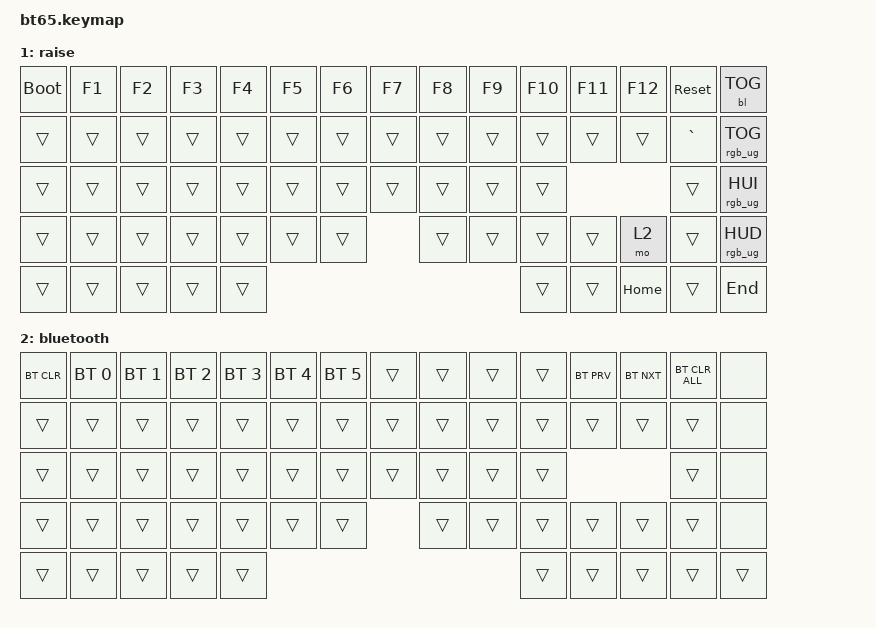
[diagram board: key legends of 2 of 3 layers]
#include <behaviors.dtsi>
#include <dt-bindings/zmk/keys.h>
#include <dt-bindings/zmk/bt.h>
#include <dt-bindings/zmk/rgb.h>
#include <dt-bindings/zmk/backlight.h>
#include <dt-bindings/zmk/ext_power.h>


/ {
    behaviors {
        bl_encoder: bl_encoder {
            compatible = "zmk,behavior-sensor-rotate";
            #sensor-binding-cells = <0>;
            bindings = <&bl BL_INC>, <&bl BL_DEC>;
        };
    };

    keymap {
        compatible = "zmk,keymap";

        default_layer {
                // ------------------------------------------------------------------------------------------------
                // | ESC |  1  |  2  |  3  |  4  |  5  |  6  |  7  |  8  |  9  |  0  |  -  |  =  |  BKSP  | MUTE |
                // | TAB  |  Q  |  W  |  E  |  R  |  T  |  Y  |  U  |  I  |  O  |  P  |  [  |  ]  |   \   | DEL  |
                // | CAPS  |  A  |  S  |  D  |  F  |  G  |  H  |  J  |  K  |  L  |  ;  |  '  |    ENTER   | PGUP |
                // |  SHIFT  |  Z  |  X  |  C  |  V  |  B  |  N  |  M  |  ,  |  .  | /  |   SHIFT    | UP | PGDN |
                // |  CTL  |  WIN  |  ALT  |             SPACE               | GLB |  RAISE  | CTL | LEFT | DN | RIGHT |
                // ------------------------------------------------------------------------------------------------
            bindings = <
                &kp ESC &kp N1 &kp N2 &kp N3 &kp N4 &kp N5 &kp N6 &kp N7 &kp  N8   &kp  N9   &kp N0 &kp MINUS &kp EQUAL &kp BKSP &kp C_MUTE
                &kp TAB  &kp Q  &kp W  &kp E  &kp R  &kp T  &kp Y  &kp U  &kp  I    &kp  O  &kp  P   &kp LBKT &kp RBKT      &kp BSLH &kp DEL
                &kp CLCK  &kp A  &kp S  &kp D  &kp F  &kp G  &kp H  &kp J  &kp  K    &kp  L  &kp SEMI &kp SQT               &kp RET &kp PG_UP
                &kp LSHFT &kp Z  &kp X  &kp C  &kp V  &kp B  &kp N  &kp M  &kp COMMA &kp DOT &kp FSLH   &kp RSHFT &kp UP &kp PG_DN
                &kp LCTRL &kp LGUI &kp LALT            &kp SPACE                          &kp GLOBE  &mo 1 &kp RCTRL &kp LEFT &kp DOWN &kp RIGHT
            >;
            sensor-bindings = <&inc_dec_kp C_VOL_UP C_VOL_DN>;
        };
        raise {
                // ------------------------------------------------------------------------------------------------
                // | BOOTLOADER |  F1  | F2  |  F3  |  F4  |  F5  |  F6  |  F7  |  F8  |  F9  |  F10  |  F11  |  F12  |  SYS_RESET  | BL |
                // | TAB  |  Q  |  W  |  E  |  R  |  T  |  Y  |  U  |  I  |  O  |  P  |  [  |  ]  |  `  | RGB_TOG |
                // | CAPS  |  A  |  S  |  D  |  F  |  G  |  H  |  J  |  K  |  L  |  ;  |  '  |    ENTER   | RGB_I |
                // |  SHIFT  |  Z  |  X  |  C  |  V  |  B  |  N  |  M  |  ,  |  .  | /  |   BLUETOOTH   | UP | RGB_D |
                // |  CTL  |  WIN  |  ALT  |             SPACE               | GLB |    | CTL | HOME | DOWN | END |
                // ------------------------------------------------------------------------------------------------
            bindings = <
                &bootloader   &kp F1 &kp F2 &kp F3 &kp F4 &kp F5 &kp F6 &kp F7 &kp F8 &kp F9 &kp F10 &kp F11 &kp F12 &sys_reset  &bl BL_TOG
                &trans &trans &trans &trans &trans &trans &trans &trans &trans &trans &trans &trans &trans            &kp GRAVE  &rgb_ug RGB_TOG
                &trans &trans &trans &trans &trans &trans &trans &trans &trans &trans &trans                        &trans       &rgb_ug RGB_HUI
                &trans &trans &trans &trans &trans &trans &trans &trans &trans &trans &trans               &mo 2       &trans    &rgb_ug RGB_HUD
                &trans &trans &trans               &trans                             &trans &trans &trans &kp HOME    &trans    &kp END
            >;
            sensor-bindings = <&bl_encoder>;
        };
        bluetooth {
                // ------------------------------------------------------------------------------------------------
                // | BT CLR |  BT 1  | BT 2  |  BT 3  |  BT 4  |  BT 5  |   |   |   |   |   |  BT PREV  | BTNEXT | BT CLR ALL  |  |
                // | TAB  |  Q  |  W  |  E  |  R  |  T  |  Y  |  U  |  I  |  O  |  P  |  [  |  ]  |  `  |   |
                // | CAPS  |  A  |  S  |  D  |  F  |  G  |  H  |  J  |  K  |  L  |  ;  |  '  |    ENTER   |   |
                // |  SHIFT  |  Z  |  X  |  C  |  V  |  B  |  N  |  M  |  ,  |  .  | /  |   SHIFT    | UP |   |
                // |  CTL  |  WIN  |  ALT  |             SPACE               | GLB |    | CTL | HOME | DOWN | END |
                // ------------------------------------------------------------------------------------------------
            bindings = <
                &bt BT_CLR &bt BT_SEL 0 &bt BT_SEL 1 &bt BT_SEL 2 &bt BT_SEL 3 &bt BT_SEL 4 &bt BT_SEL 5 &trans &trans &trans &trans &bt BT_PRV &bt BT_NXT &bt BT_CLR_ALL  &none
                &trans &trans &trans &trans &trans &trans &trans &trans &trans &trans &trans &trans &trans            &trans  &none
                &trans &trans &trans &trans &trans &trans &trans &trans &trans &trans &trans                        &trans       &none
                &trans &trans &trans &trans &trans &trans &trans &trans &trans &trans &trans               &trans      &trans    &none
                &trans &trans &trans               &trans                             &trans &trans &trans &trans    &trans    &trans
            >;
            sensor-bindings = <&bl_encoder>;
        };
    };
};
